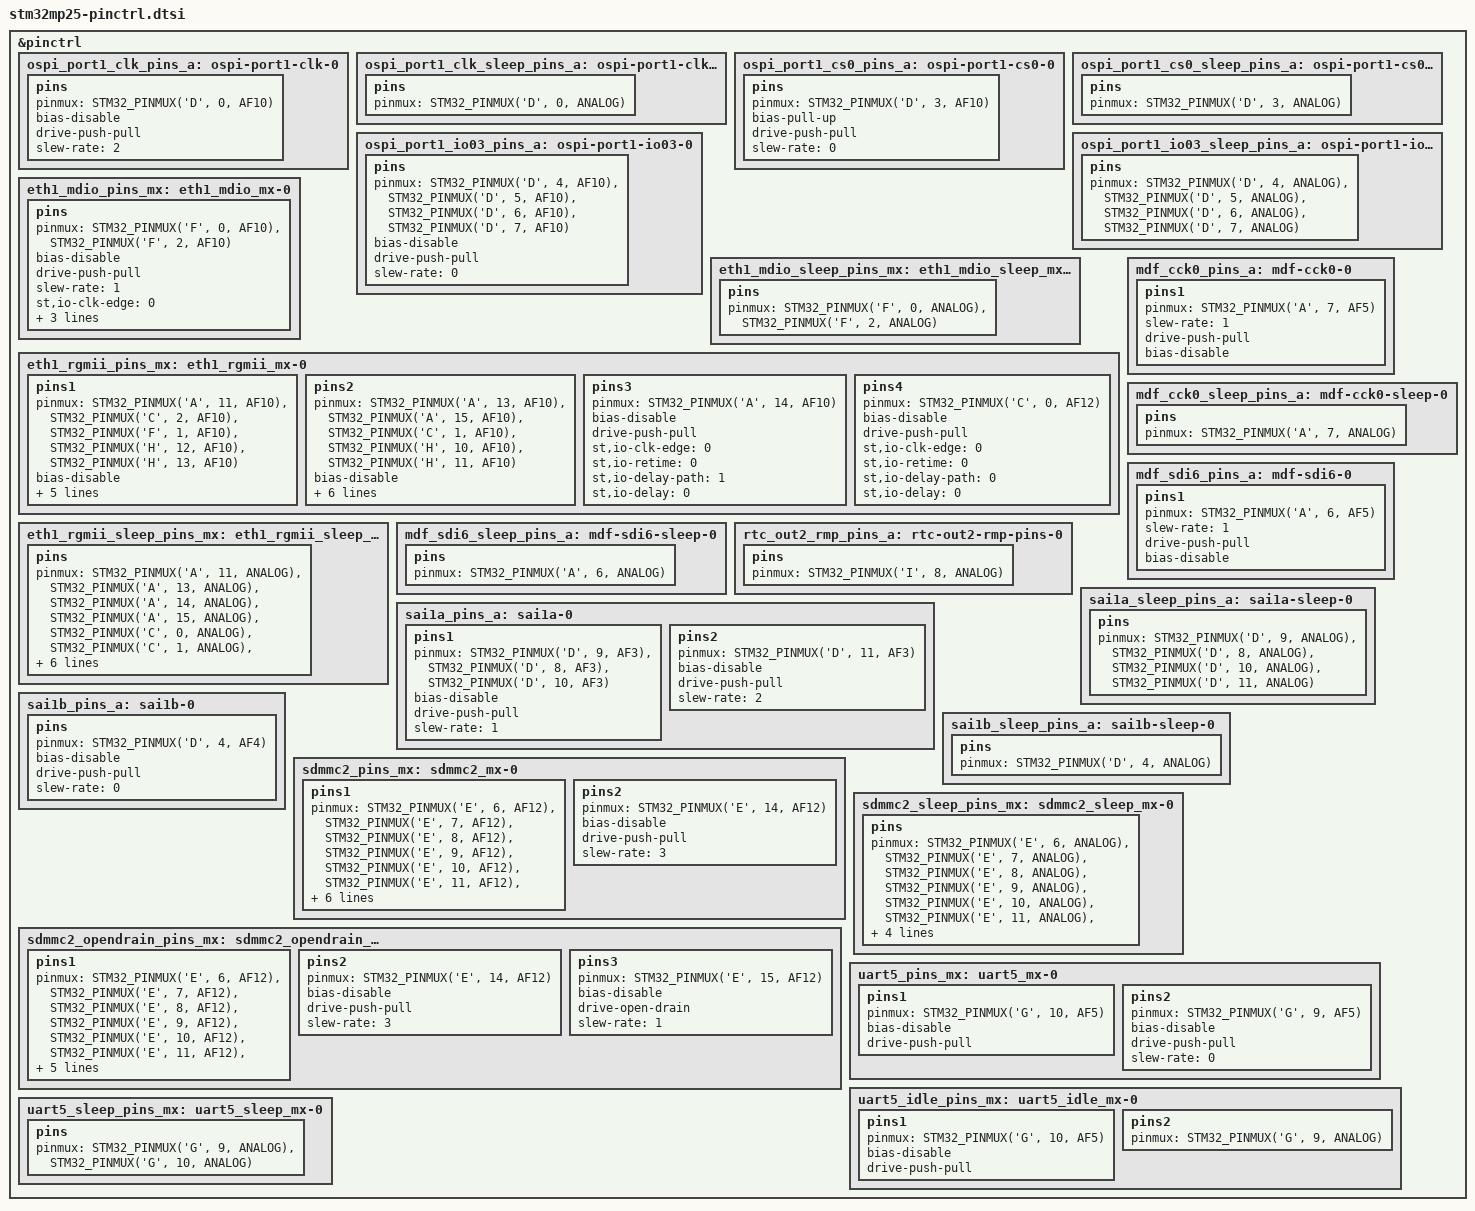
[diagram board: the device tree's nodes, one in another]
// SPDX-License-Identifier: (GPL-2.0-or-later OR BSD-3-Clause)
/*
 * Copyright (C) STMicroelectronics 2023 - All Rights Reserved
 * Author: Alexandre Torgue <alexandre.torgue@foss.st.com> for STMicroelectronics.
 */
#include <dt-bindings/pinctrl/stm32-pinfunc.h>

&pinctrl {
ospi_port1_clk_pins_a: ospi-port1-clk-0 {
		pins {
			pinmux = <STM32_PINMUX('D', 0, AF10)>; /* OSPI1_CLK */
			bias-disable;
			drive-push-pull;
			slew-rate = <2>;
		};
	};

	ospi_port1_clk_sleep_pins_a: ospi-port1-clk-sleep-0 {
		pins {
			pinmux = <STM32_PINMUX('D', 0, ANALOG)>; /* OSPI1_CLK */
		};
	};

	ospi_port1_cs0_pins_a: ospi-port1-cs0-0 {
		pins {
			pinmux = <STM32_PINMUX('D', 3, AF10)>; /* OSPI_NCS0 */
			bias-pull-up;
			drive-push-pull;
			slew-rate = <0>;
		};
	};

	ospi_port1_cs0_sleep_pins_a: ospi-port1-cs0-sleep-0 {
		pins {
			pinmux = <STM32_PINMUX('D', 3, ANALOG)>; /* OSPI_NCS0 */
		};
	};

	ospi_port1_io03_pins_a: ospi-port1-io03-0 {
		pins {
			pinmux = <STM32_PINMUX('D', 4, AF10)>, /* OSPI_IO0 */
				 <STM32_PINMUX('D', 5, AF10)>, /* OSPI_IO1 */
				 <STM32_PINMUX('D', 6, AF10)>, /* OSPI_IO2 */
				 <STM32_PINMUX('D', 7, AF10)>; /* OSPI_IO3 */
			bias-disable;
			drive-push-pull;
			slew-rate = <0>;
		};
	};

	ospi_port1_io03_sleep_pins_a: ospi-port1-io03-sleep-0 {
		pins {
			pinmux = <STM32_PINMUX('D', 4, ANALOG)>, /* OSPI_IO0 */
				 <STM32_PINMUX('D', 5, ANALOG)>, /* OSPI_IO1 */
				 <STM32_PINMUX('D', 6, ANALOG)>, /* OSPI_IO2 */
				 <STM32_PINMUX('D', 7, ANALOG)>; /* OSPI_IO3 */
		};
	};


	eth1_mdio_pins_mx: eth1_mdio_mx-0 {
		pins {
			pinmux = <STM32_PINMUX('F', 0, AF10)>, /* ETH1_MDC */
					 <STM32_PINMUX('F', 2, AF10)>; /* ETH1_MDIO */
			bias-disable;
			drive-push-pull;
			slew-rate = <1>;
			st,io-clk-edge = <0>;
			st,io-retime = <0>;
			st,io-delay-path = <0>;
			st,io-delay = <0>;
		};
	};

	eth1_mdio_sleep_pins_mx: eth1_mdio_sleep_mx-0 {
		pins {
			pinmux = <STM32_PINMUX('F', 0, ANALOG)>, /* ETH1_MDC */
					 <STM32_PINMUX('F', 2, ANALOG)>; /* ETH1_MDIO */
		};
	};

	eth1_rgmii_pins_mx: eth1_rgmii_mx-0 {
		pins1 {
			pinmux = <STM32_PINMUX('A', 11, AF10)>, /* ETH1_RGMII_RX_CTL */
					 <STM32_PINMUX('C', 2, AF10)>, /* ETH1_RGMII_RXD1 */
					 <STM32_PINMUX('F', 1, AF10)>, /* ETH1_RGMII_RXD0 */
					 <STM32_PINMUX('H', 12, AF10)>, /* ETH1_RGMII_RXD2 */
					 <STM32_PINMUX('H', 13, AF10)>; /* ETH1_RGMII_RXD3 */
			bias-disable;
			drive-push-pull;
			st,io-clk-edge = <1>;
			st,io-retime = <1>;
			st,io-delay-path = <0>;
			st,io-delay = <0>;
		};
		pins2 {
			pinmux = <STM32_PINMUX('A', 13, AF10)>, /* ETH1_RGMII_TX_CTL */
					 <STM32_PINMUX('A', 15, AF10)>, /* ETH1_RGMII_TXD0 */
					 <STM32_PINMUX('C', 1, AF10)>, /* ETH1_RGMII_TXD1 */
					 <STM32_PINMUX('H', 10, AF10)>, /* ETH1_RGMII_TXD2 */
					 <STM32_PINMUX('H', 11, AF10)>; /* ETH1_RGMII_TXD3 */
			bias-disable;
			drive-push-pull;
			slew-rate = <2>;
			st,io-clk-edge = <1>;
			st,io-retime = <1>;
			st,io-delay-path = <0>;
			st,io-delay = <0>;
		};
		pins3 {
			pinmux = <STM32_PINMUX('A', 14, AF10)>; /* ETH1_RGMII_RX_CLK */
			bias-disable;
			drive-push-pull;
			st,io-clk-edge = <0>;
			st,io-retime = <0>;
			st,io-delay-path = <1>;
			st,io-delay = <0>;
		};
		pins4 {
			pinmux = <STM32_PINMUX('C', 0, AF12)>; /* ETH1_RGMII_GTX_CLK */
			bias-disable;
			drive-push-pull;
			st,io-clk-edge = <0>;
			st,io-retime = <0>;
			st,io-delay-path = <0>;
			st,io-delay = <0>;
		};
	};

	eth1_rgmii_sleep_pins_mx: eth1_rgmii_sleep_mx-0 {
		pins {
			pinmux = <STM32_PINMUX('A', 11, ANALOG)>, /* ETH1_RGMII_RX_CTL */
					 <STM32_PINMUX('A', 13, ANALOG)>, /* ETH1_RGMII_TX_CTL */
					 <STM32_PINMUX('A', 14, ANALOG)>, /* ETH1_RGMII_RX_CLK */
					 <STM32_PINMUX('A', 15, ANALOG)>, /* ETH1_RGMII_TXD0 */
					 <STM32_PINMUX('C', 0, ANALOG)>, /* ETH1_RGMII_GTX_CLK */
					 <STM32_PINMUX('C', 1, ANALOG)>, /* ETH1_RGMII_TXD1 */
					 <STM32_PINMUX('C', 2, ANALOG)>, /* ETH1_RGMII_RXD1 */
					 <STM32_PINMUX('F', 1, ANALOG)>, /* ETH1_RGMII_RXD0 */
					 <STM32_PINMUX('H', 10, ANALOG)>, /* ETH1_RGMII_TXD2 */
					 <STM32_PINMUX('H', 11, ANALOG)>, /* ETH1_RGMII_TXD3 */
					 <STM32_PINMUX('H', 12, ANALOG)>, /* ETH1_RGMII_RXD2 */
					 <STM32_PINMUX('H', 13, ANALOG)>; /* ETH1_RGMII_RXD3 */
		};
	};
	
	mdf_cck0_pins_a: mdf-cck0-0 {
		pins1 {
			pinmux = <STM32_PINMUX('A', 7, AF5)>; /* MDF1_CCK */
			slew-rate = <1>;
			drive-push-pull;
			bias-disable;
		};
	};

	mdf_cck0_sleep_pins_a: mdf-cck0-sleep-0 {
		pins {
			pinmux = <STM32_PINMUX('A', 7, ANALOG)>; /* MDF1_CCK */
		};
	};

	mdf_sdi6_pins_a: mdf-sdi6-0 {
		pins1 {
			pinmux = <STM32_PINMUX('A', 6, AF5)>; /* MDF1_SDI6 */
			slew-rate = <1>;
			drive-push-pull;
			bias-disable;
		};
	};

	mdf_sdi6_sleep_pins_a: mdf-sdi6-sleep-0 {
		pins {
			pinmux = <STM32_PINMUX('A', 6, ANALOG)>; /* MDF1_SDI6 */
		};
	};

	

	rtc_out2_rmp_pins_a: rtc-out2-rmp-pins-0 {
		pins {
			pinmux = <STM32_PINMUX('I', 8, ANALOG)>; /* RTC_OUT2_RMP */
		};
	};

	sai1a_pins_a: sai1a-0 {
		pins1 {
			pinmux = <STM32_PINMUX('D', 9, AF3)>, /* SAI1_SD_A */
				 <STM32_PINMUX('D', 8, AF3)>, /* SAI1_FS_A */
				 <STM32_PINMUX('D', 10, AF3)>; /* SAI1_SCK_A */
			bias-disable;
			drive-push-pull;
			slew-rate = <1>;
		};
		pins2 {
			pinmux = <STM32_PINMUX('D', 11, AF3)>; /* SAI1_MCLK_A */
			bias-disable;
			drive-push-pull;
			slew-rate = <2>;
		};
	};

	sai1a_sleep_pins_a: sai1a-sleep-0 {
		pins {
			pinmux = <STM32_PINMUX('D', 9, ANALOG)>, /* SAI1_SD_A */
				 <STM32_PINMUX('D', 8, ANALOG)>, /* SAI1_FS_A */
				 <STM32_PINMUX('D', 10, ANALOG)>, /* SAI1_SCK_A */
				 <STM32_PINMUX('D', 11, ANALOG)>; /* SAI1_MCLK_A */
		};
	};

	sai1b_pins_a: sai1b-0 {
		pins {
			pinmux = <STM32_PINMUX('D', 4, AF4)>; /* SAI1_SD_B */
			bias-disable;
			drive-push-pull;
			slew-rate = <0>;
		};
	};

	sai1b_sleep_pins_a: sai1b-sleep-0 {
		pins {
			pinmux = <STM32_PINMUX('D', 4, ANALOG)>; /* SAI1_SD_B */
		};
	};

	
	sdmmc2_pins_mx: sdmmc2_mx-0 {
		pins1 {
			pinmux = <STM32_PINMUX('E', 6, AF12)>, /* SDMMC2_D6 */
					 <STM32_PINMUX('E', 7, AF12)>, /* SDMMC2_D7 */
					 <STM32_PINMUX('E', 8, AF12)>, /* SDMMC2_D2 */
					 <STM32_PINMUX('E', 9, AF12)>, /* SDMMC2_D5 */
					 <STM32_PINMUX('E', 10, AF12)>, /* SDMMC2_D4 */
					 <STM32_PINMUX('E', 11, AF12)>, /* SDMMC2_D1 */
					 <STM32_PINMUX('E', 12, AF12)>, /* SDMMC2_D3 */
					 <STM32_PINMUX('E', 13, AF12)>, /* SDMMC2_D0 */
					 <STM32_PINMUX('E', 15, AF12)>; /* SDMMC2_CMD */
			bias-disable;
			drive-push-pull;
			slew-rate = <1>;
		};
		pins2 {
			pinmux = <STM32_PINMUX('E', 14, AF12)>; /* SDMMC2_CK */
			bias-disable;
			drive-push-pull;
			slew-rate = <3>;
		};
	};
	
	sdmmc2_opendrain_pins_mx: sdmmc2_opendrain_mx-0 {
		pins1 {
			pinmux = <STM32_PINMUX('E', 6, AF12)>, /* SDMMC2_D6 */
					 <STM32_PINMUX('E', 7, AF12)>, /* SDMMC2_D7 */
					 <STM32_PINMUX('E', 8, AF12)>, /* SDMMC2_D2 */
					 <STM32_PINMUX('E', 9, AF12)>, /* SDMMC2_D5 */
					 <STM32_PINMUX('E', 10, AF12)>, /* SDMMC2_D4 */
					 <STM32_PINMUX('E', 11, AF12)>, /* SDMMC2_D1 */
					 <STM32_PINMUX('E', 12, AF12)>, /* SDMMC2_D3 */
					 <STM32_PINMUX('E', 13, AF12)>; /* SDMMC2_D0 */
			bias-disable;
			drive-push-pull;
			slew-rate = <1>;
		};
		pins2 {
			pinmux = <STM32_PINMUX('E', 14, AF12)>; /* SDMMC2_CK */
			bias-disable;
			drive-push-pull;
			slew-rate = <3>;
		};
		pins3 {
			pinmux = <STM32_PINMUX('E', 15, AF12)>; /* SDMMC2_CMD */
			bias-disable;
			drive-open-drain;
			slew-rate = <1>;
		};
	};
	
	sdmmc2_sleep_pins_mx: sdmmc2_sleep_mx-0 {
		pins {
			pinmux = <STM32_PINMUX('E', 6, ANALOG)>, /* SDMMC2_D6 */
					 <STM32_PINMUX('E', 7, ANALOG)>, /* SDMMC2_D7 */
					 <STM32_PINMUX('E', 8, ANALOG)>, /* SDMMC2_D2 */
					 <STM32_PINMUX('E', 9, ANALOG)>, /* SDMMC2_D5 */
					 <STM32_PINMUX('E', 10, ANALOG)>, /* SDMMC2_D4 */
					 <STM32_PINMUX('E', 11, ANALOG)>, /* SDMMC2_D1 */
					 <STM32_PINMUX('E', 12, ANALOG)>, /* SDMMC2_D3 */
					 <STM32_PINMUX('E', 13, ANALOG)>, /* SDMMC2_D0 */
					 <STM32_PINMUX('E', 14, ANALOG)>, /* SDMMC2_CK */
					 <STM32_PINMUX('E', 15, ANALOG)>; /* SDMMC2_CMD */
		};
	};

	

	uart5_pins_mx: uart5_mx-0 {
		pins1 {
			pinmux = <STM32_PINMUX('G', 10, AF5)>; /* UART5_RX */
			bias-disable;
			drive-push-pull;
		};
		pins2 {
			pinmux = <STM32_PINMUX('G', 9, AF5)>; /* UART5_TX */
			bias-disable;
			drive-push-pull;
			slew-rate = <0>;
		};
	};

	uart5_idle_pins_mx: uart5_idle_mx-0 {
		pins1 {
			pinmux = <STM32_PINMUX('G', 10, AF5)>; /* UART5_RX */
			bias-disable;
			drive-push-pull;
		};
		pins2 {
			pinmux = <STM32_PINMUX('G', 9, ANALOG)>; /* UART5_TX */
		};
	};
	
	uart5_sleep_pins_mx: uart5_sleep_mx-0 {
		pins {
			pinmux = <STM32_PINMUX('G', 9, ANALOG)>, /* UART5_TX */
					 <STM32_PINMUX('G', 10, ANALOG)>; /* UART5_RX */
		};
	};

};

